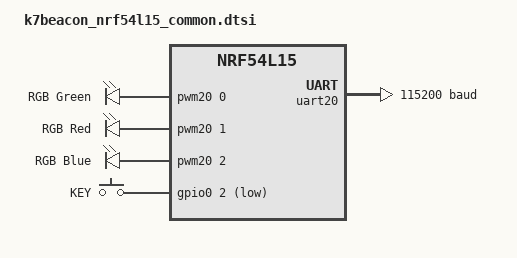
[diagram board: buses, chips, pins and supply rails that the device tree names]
/*
 * SPDX-License-Identifier: Apache-2.0
 *
 * KKM K7 Beacon — nRF54L15. Pins from K7P54L Rev V1.04.
 *
 * The RGB is an LTST-C19HE1WT-H with its common pin tied to VDDS: COMMON
 * ANODE, so every channel is ACTIVE LOW and the PWM channels are declared
 * PWM_POLARITY_INVERTED. Getting that backwards gives you an LED that is on
 * whenever it should be off, which reads as a dead board showing a stuck
 * colour rather than as a polarity mistake.
 */

#include "k7beacon_nrf54l15-pinctrl.dtsi"
#include <zephyr/dt-bindings/input/input-event-codes.h>

/ {
	/*
	 * All three channels on pwm20. P1 is LP-domain, which the nRF54L15's
	 * PWM peripherals can reach — so this board does real colour rather
	 * than on/off.
	 */
	rgb_led: pwmleds {
		compatible = "pwm-leds";

		led_g: led_g {
			pwms = <&pwm20 0 PWM_USEC(250) PWM_POLARITY_INVERTED>;
			label = "RGB Green";
		};

		led_r: led_r {
			pwms = <&pwm20 1 PWM_USEC(250) PWM_POLARITY_INVERTED>;
			label = "RGB Red";
		};

		led_b: led_b {
			pwms = <&pwm20 2 PWM_USEC(250) PWM_POLARITY_INVERTED>;
			label = "RGB Blue";
		};
	};

	buttons: buttons {
		compatible = "gpio-keys";

		usr_btn: usr-btn {
			/* SW1 to GND, no external pull-up — the internal one is
			 * not optional here. */
			gpios = <&gpio0 2 (GPIO_PULL_UP | GPIO_ACTIVE_LOW)>;
			label = "KEY";
			zephyr,code = <INPUT_KEY_0>;
		};
	};

	aliases {
		led-red = &led_r;
		led-green = &led_g;
		led-blue = &led_b;
		sw0 = &usr_btn;
		buttons = &buttons;
		watchdog0 = &wdt31;
	};
};

&uart20 {
	current-speed = <115200>;
	pinctrl-0 = <&uart20_default>;
	pinctrl-1 = <&uart20_sleep>;
	pinctrl-names = "default", "sleep";
};

&pwm20 {
	pinctrl-0 = <&pwm20_default>;
	pinctrl-1 = <&pwm20_sleep>;
	pinctrl-names = "default", "sleep";
};
